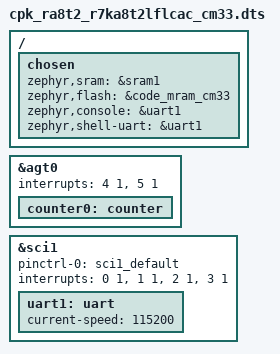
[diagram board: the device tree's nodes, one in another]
/*
 * SPDX-FileCopyrightText: Copyright (c) 2026 Process Mission
 * SPDX-License-Identifier: Apache-2.0
 */

/dts-v1/;

#include <renesas/ra/ra8/r7ka8t2lflcac_cm33.dtsi>
#include "cpk_ra8t2.dtsi"

/ {
	chosen {
		zephyr,sram = &sram1;
		zephyr,flash = &code_mram_cm33;
		zephyr,console = &uart1;
		zephyr,shell-uart = &uart1;
	};
};

&agt0 {
	interrupts = <4 1>, <5 1>;
	interrupt-names = "agti", "agtcmai";

	counter0: counter {};
};

&sci1 {
	pinctrl-0 = <&sci1_default>;
	pinctrl-names = "default";
	interrupts = <0 1>, <1 1>, <2 1>, <3 1>;
	interrupt-names = "rxi", "txi", "tei", "eri";
	status = "okay";

	uart1: uart {
		current-speed = <115200>;
		status = "okay";
	};
};
